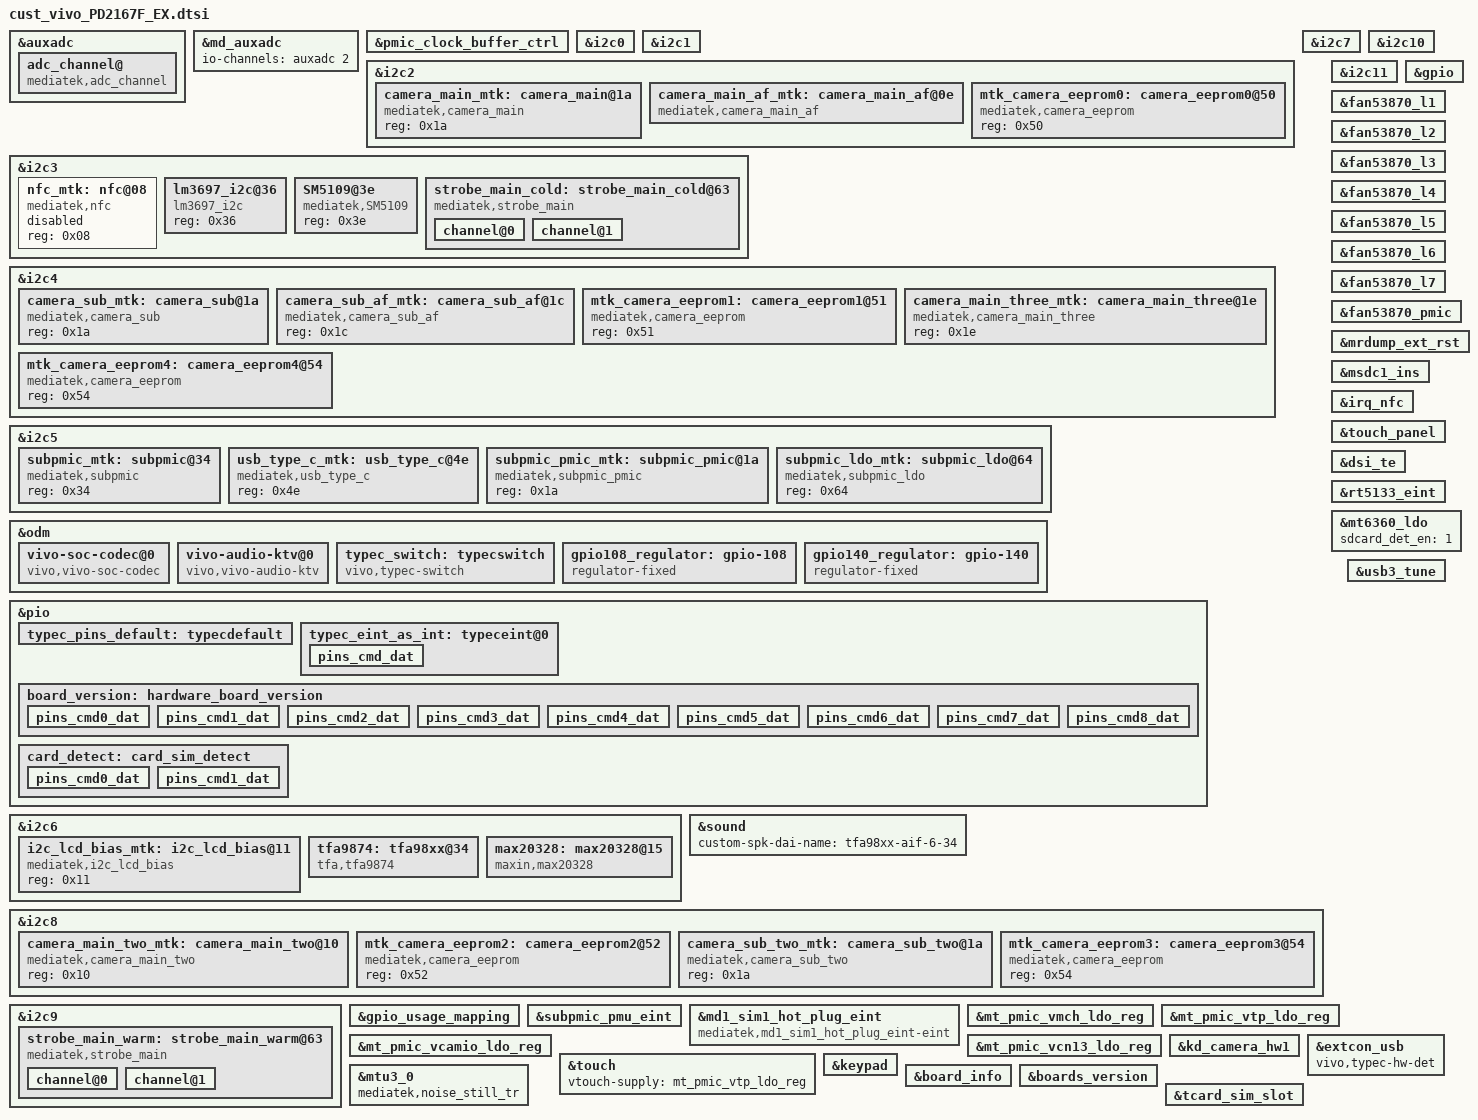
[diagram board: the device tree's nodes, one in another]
/*
 * Generated by MTK SP DrvGen Version: 3.5.160809 for MT6877.
 * 2021-08-30 17:19:41
 * Do Not Modify The File.
 * Copyright Mediatek Inc. (c) 2016.
*/

/*************************
 * ADC DTSI File
*************************/

&auxadc {
	adc_channel@ {
		compatible = "mediatek,adc_channel";
		mediatek,temperature0 = <0>;
		mediatek,temperature1 = <1>;
		mediatek,adc_fdd_rf_params_dynamic_custom_ch = <2>;
		status = "okay";
	};
};
&md_auxadc {
	io-channels = <&auxadc 2>;
};


/*************************
 * CLK_BUF DTSI File
*************************/

&pmic_clock_buffer_ctrl {
	mediatek,clkbuf-quantity = <7>;
	mediatek,clkbuf-config = <2 1 2 2 0 0 1>;
	mediatek,clkbuf-output-impedance = <3 4 3 4 0 0 3>;
	mediatek,clkbuf-controls-for-desense = <0 4 0 4 0 0 0>;
	status = "okay";
};


/*************************
 * I2C DTSI File
*************************/

&i2c0 {
	#address-cells = <1>;
	#size-cells = <0>;
	clock-frequency = <400000>;
	mediatek,use-open-drain;
	#include "fan53870.dtsi"
};

&i2c1 {
	#address-cells = <1>;
	#size-cells = <0>;
	clock-frequency = <400000>;
	mediatek,use-open-drain;
};

&i2c2 {
	#address-cells = <1>;
	#size-cells = <0>;
	clock-frequency = <400000>;
	mediatek,use-open-drain;
	camera_main_mtk:camera_main@1a {
		compatible = "mediatek,camera_main";
		reg = <0x1a>;
		status = "okay";
	};

	camera_main_af_mtk:camera_main_af@0e {
		compatible = "mediatek,camera_main_af";
		reg = <0x0e>;
		status = "okay";
	};
	mtk_camera_eeprom0:camera_eeprom0@50 {
		compatible = "mediatek,camera_eeprom";
		reg = <0x50>;
		status = "okay";
	};

};

&i2c3 {
	#address-cells = <1>;
	#size-cells = <0>;
	clock-frequency = <400000>;
	mediatek,use-open-drain;
	nfc_mtk:nfc@08 {
		compatible = "mediatek,nfc";
		reg = <0x08>;
		status = "disabled";
	};

	lm3697_i2c@36 {
		compatible = "lm3697_i2c";
		reg = <0x36>;
		status = "okay";
	};
	SM5109@3e {
		compatible = "mediatek,SM5109";
		reg = <0x3e>;
		status = "okay";
	};
	strobe_main_cold: strobe_main_cold@63 {
		compatible = "mediatek,strobe_main";
		reg = <0x63>;
		status = "okay";
		flash_enable-supply = <&gpio108_regulator>;
		torch_enable-supply = <&gpio140_regulator>;
	};
};

&i2c4 {
	#address-cells = <1>;
	#size-cells = <0>;
	clock-frequency = <400000>;
	mediatek,use-open-drain;
	camera_sub_mtk:camera_sub@1a {
		compatible = "mediatek,camera_sub";
		reg = <0x1a>;
		status = "okay";
	};
	camera_sub_af_mtk:camera_sub_af@1c {
		compatible = "mediatek,camera_sub_af";
		reg = <0x1c>;
		status = "okay";
	};
	mtk_camera_eeprom1:camera_eeprom1@51 {
		compatible = "mediatek,camera_eeprom";
		reg = <0x51>;
		status = "okay";
	};
	camera_main_three_mtk:camera_main_three@1e {
		compatible = "mediatek,camera_main_three";
		reg = <0x1e>;
		status = "okay";
	};
	mtk_camera_eeprom4:camera_eeprom4@54 {
		compatible = "mediatek,camera_eeprom";
		reg = <0x54>;
		status = "okay";
	};

};

&i2c5 {
	#address-cells = <1>;
	#size-cells = <0>;
	clock-frequency = <3400000>;
	mediatek,use-push-pull;
	subpmic_mtk:subpmic@34 {
		compatible = "mediatek,subpmic";
		reg = <0x34>;
		status = "okay";
	};

	usb_type_c_mtk:usb_type_c@4e {
		compatible = "mediatek,usb_type_c";
		reg = <0x4e>;
		status = "okay";
	};

	subpmic_pmic_mtk:subpmic_pmic@1a {
		compatible = "mediatek,subpmic_pmic";
		reg = <0x1a>;
		status = "okay";
	};

	subpmic_ldo_mtk:subpmic_ldo@64 {
		compatible = "mediatek,subpmic_ldo";
		reg = <0x64>;
		status = "okay";
	};

};

/* vivo audio dxl add start */
&odm {
	vivo-soc-codec@0 {
		compatible = "vivo,vivo-soc-codec";
		status = "okay";
	};
	vivo-audio-ktv@0 {
		compatible = "vivo,vivo-audio-ktv";
		status = "okay";
	};

	typec_switch:typecswitch {
			compatible = "vivo,typec-switch";
			interrupt-parent = <&pio>;
			interrupts = <17 IRQ_TYPE_LEVEL_LOW 17 0>;
			deb-gpios = <&pio 17 0>;
			debounce = <256000>;
			need_config_Max14743 = <1>;
			pinctrl-names = "default", "typec_eint_as_int";
			pinctrl-0 = <&typec_pins_default>;
			pinctrl-1 = <&typec_eint_as_int>;
			status = "okay";
	};
};

&pio {
	typec_pins_default: typecdefault {
	};
	typec_eint_as_int: typeceint@0 {
			pins_cmd_dat {
					pinmux = <PINMUX_GPIO17__FUNC_GPIO17>;
					slew-rate = <0>;
					/*audio_v: archer modfiy bacause cancel hardware comparator,so not the interrupt.*/
					/*bias-disable;*/
					bias-pull-up;
					input-enable;
			};
	};
};
/* vivo audio dxl add end */

&i2c6 {
	#address-cells = <1>;
	#size-cells = <0>;
	clock-frequency = <400000>;
	mediatek,use-open-drain;
	i2c_lcd_bias_mtk:i2c_lcd_bias@11 {
		compatible = "mediatek,i2c_lcd_bias";
		reg = <0x11>;
		status = "okay";
	};
	/* vivo audio dxl add start */
	tfa9874: tfa98xx@34 {
		status = "okay";
		compatible = "tfa,tfa9874";
		#sound-dai-cells = <1>;
		reg = <0x34>;
		vivo_dtbo_version = "version:5"; /*audio_v: archer add for test dtbo is update*/
		vivo,tfa98xx-version = "tfa9874";
		vivo,tfa98xx-config = "tfa98xx_PD2167F_EX.cnt";
		vivo,tfa98xx-impedance-min = <6000>;
		vivo,tfa98xx-impedance-max = <10000>;
		vivo,tfa98xx-frequency-min = <600>;
		vivo,tfa98xx-frequency-max = <900>;
		vivo,tfa98xx-Qt-min = <110>;
		reset-gpio = <&pio 111 0>;
	};

	max20328:max20328@15 {
		status = "okay";
		#sound-dai-cells = <0>;
		compatible = "maxin,max20328";
		reg = <0x15>;
		max,usbc-ic-mode = <0>; /* max20328: 0; fsa4480: 1 */
		jack-type = <1>;   /*0:3.5mm, 1:Type-c*/
		switch-type = <0>; /*0:max20328, 1:FS4480*/
	};
	/* vivo audio dxl add end */
};

/* vivo audio dxl add start */
&sound {
	custom-spk-dai-name = "tfa98xx-aif-6-34";
};
/* vivo audio dxl add end */

&i2c7 {
	#address-cells = <1>;
	#size-cells = <0>;
	clock-frequency = <400000>;
	mediatek,use-open-drain;
};

&i2c8 {
	#address-cells = <1>;
	#size-cells = <0>;
	clock-frequency = <400000>;
	mediatek,use-open-drain;
	camera_main_two_mtk:camera_main_two@10 {
		compatible = "mediatek,camera_main_two";
		reg = <0x10>;
		status = "okay";
	};
	mtk_camera_eeprom2:camera_eeprom2@52 {
		compatible = "mediatek,camera_eeprom";
		reg = <0x52>;
		status = "okay";
	};
	camera_sub_two_mtk:camera_sub_two@1a {
		compatible = "mediatek,camera_sub_two";
		reg = <0x1a>;
		status = "okay";
	};
	mtk_camera_eeprom3:camera_eeprom3@54 {
		compatible = "mediatek,camera_eeprom";
		reg = <0x54>;
		status = "okay";
	};

};

&i2c9 {
	#address-cells = <1>;
	#size-cells = <0>;
	clock-frequency = <400000>;
	mediatek,use-open-drain;
	strobe_main_warm: strobe_main_warm@63 {
		compatible = "mediatek,strobe_main";
		reg = <0x63>;
		status = "okay";
		flash_enable-supply = <&gpio108_regulator>;
		torch_enable-supply = <&gpio140_regulator>;
	};
};

&i2c10 {
	#address-cells = <1>;
	#size-cells = <0>;
	clock-frequency = <400000>;
	mediatek,use-open-drain;
};

&i2c11 {
	#address-cells = <1>;
	#size-cells = <0>;
	clock-frequency = <400000>;
	mediatek,use-open-drain;
};



/*************************
 * GPIO DTSI File
*************************/

&gpio_usage_mapping {
	GPIO_RF_PWREN_RST_PIN = <&pio 75 0>;
	GPIO_FDD_BAND_SUPPORT_DETECT_1ST_PIN = <&pio 92 0>;
	GPIO_FDD_BAND_SUPPORT_DETECT_2ND_PIN = <&pio 35 0>;
	GPIO_SIM2_SIO = <&pio 170 0>;
	GPIO_SIM2_SCLK = <&pio 171 0>;
	GPIO_SIM2_SRST = <&pio 172 0>;
	GPIO_SIM1_SRST = <&pio 173 0>;
	GPIO_SIM1_SCLK = <&pio 174 0>;
	GPIO_SIM1_SIO = <&pio 175 0>;
	GPIO_SIM1_HOT_PLUG = <&pio 176 0>;
};

&gpio{
	gpio_init_default = <0 0 0 0 1 1 1>,
		<1 0 0 0 1 0 1>,
		<2 0 0 0 1 1 1>,
		<3 0 0 0 0 0 1>, /* modify by dxl to disable max20328 INT pullen */
		<4 0 0 0 1 1 1>,
		<5 0 0 0 1 1 1>,
		<6 0 0 0 0 0 1>,
		<7 0 0 0 0 0 0>,
		<8 0 0 0 1 1 0>,
		<9 0 0 0 1 0 0>,
		<10 0 1 0 1 0 1>,
		<11 0 0 0 1 0 0>,
		<12 0 1 0 0 0 0>,//fan53870 rst
		<13 0 0 0 1 0 0>,//fan53870 int
		<14 0 0 0 1 1 1>,
		<15 0 1 0 0 0 1>,
		<16 7 0 0 1 1 0>,
		<17 7 0 0 1 1 0>,
		<18 0 1 0 0 0 0>,
		<19 0 1 0 0 0 0>,
		<20 0 0 0 0 0 1>,
		<21 0 1 0 1 0 0>,
		<22 0 1 0 1 0 0>,
		<23 7 0 0 1 1 0>,
		<24 0 0 0 1 1 0>,
		<25 1 0 0 0 0 0>,
		<26 1 0 0 1 1 0>,
		<27 0 1 1 1 1 0>,
		<28 1 0 0 1 1 0>,
		<29 0 0 0 0 0 1>,
		<30 0 0 0 0 0 1>,
		<31 0 0 0 0 0 1>,
		<32 1 0 0 1 1 0>,
		<33 1 0 0 1 1 0>,
		<34 1 0 0 1 1 0>,
		<35 0 0 0 1 1 0>,
		<36 1 0 0 1 1 1>,
		<37 1 0 0 1 1 1>,
		<38 1 0 0 1 1 1>,
		<39 1 0 0 1 0 1>,
		<40 0 1 0 0 0 0>,
		<41 1 0 0 0 0 1>,
		<42 1 0 0 0 0 1>,
		<43 1 0 0 1 0 1>,
		<44 1 0 0 1 0 1>,
		<45 1 0 0 1 1 1>,
		<46 1 0 0 0 0 0>,
		<47 1 0 0 0 0 0>,
		<48 1 0 0 0 0 0>,
		<49 1 0 0 0 0 0>,
		<50 1 0 0 1 0 0>,
		<51 1 0 0 1 0 0>,
		<52 1 0 0 1 0 0>,
		<53 1 0 0 1 0 0>,
		<54 1 0 0 1 0 1>,
		<55 1 0 0 1 0 0>,
		<56 1 0 0 1 0 0>,
		<57 1 0 0 1 0 0>,
		<58 1 0 0 1 0 0>,
		<59 1 0 0 1 0 0>,
		<60 1 0 0 0 0 1>,
		<61 1 0 0 0 0 1>,
		<62 1 0 0 0 0 1>,
		<63 1 0 0 0 0 1>,
		<64 1 0 0 1 1 1>,//fan53870 i2c0 scl
		<65 1 0 0 1 1 1>,//fan53870 i2c0 sda
		<66 1 0 0 1 0 1>,
		<67 1 0 0 1 0 1>,
		<68 1 0 0 0 0 0>,
		<69 1 0 0 1 0 0>,
		<70 1 0 0 1 0 1>,
		<71 1 0 0 0 0 1>,
		<72 1 0 0 0 0 1>,
		<73 1 0 0 0 0 1>,
		<74 1 0 0 0 0 1>,
		<75 0 1 1 1 0 1>,
		<76 1 0 0 0 0 1>,
		<77 0 0 0 1 1 0>,
		<78 1 0 0 0 0 1>,
		<79 1 0 0 0 0 1>,
		<80 0 0 0 1 1 0>,
		<81 0 0 0 1 1 0>,
		<82 1 0 0 0 0 0>,
		<83 1 0 0 1 0 0>,
		<84 1 0 0 0 0 0>,
		<85 1 0 0 1 0 0>,
		<86 1 0 0 1 0 1>,
		<87 0 0 0 1 1 0>,
		<88 1 0 0 0 0 1>,
		<89 0 0 0 1 1 0>,
		<90 1 0 0 0 0 1>,
		<91 1 0 0 0 0 1>,
		<92 0 0 0 1 1 0>,
		<93 1 0 0 0 0 1>,
		<94 0 0 0 1 1 0>,
		<95 1 0 0 0 0 1>,
		<96 0 0 0 1 1 0>,
		<97 1 0 0 0 0 1>,
		<98 0 1 0 1 0 1>,
		<99 0 1 0 1 0 1>,
		<100 0 1 0 1 0 1>,
		<101 0 1 0 1 0 1>,
		<102 1 0 0 1 1 0>,
		<103 1 0 0 1 1 0>,
		<104 1 0 0 1 1 0>,
		<105 1 0 0 1 1 0>,
		<106 1 0 0 1 1 0>,
		<107 0 1 1 0 0 1>,
		<108 0 1 0 0 0 0>,//flash en
		<109 0 1 0 1 0 0>,//usb sel
		<110 0 1 0 1 0 0>,//bat id ctl
		<111 0 1 0 1 0 0>,
		<112 1 0 0 1 1 0>,
		<113 0 0 0 1 1 0>,
		<114 0 0 0 1 1 0>,
		<115 2 0 0 1 0 1>,
		<116 1 0 0 1 1 1>,
		<117 0 0 0 1 1 0>,
		<118 0 0 0 1 1 0>,
		<119 0 0 0 1 1 0>,
		<120 1 0 0 1 1 0>,
		<121 0 0 0 1 1 0>,
		<122 7 0 0 1 1 1>,
		<123 7 0 0 1 1 0>,
		<124 7 0 0 1 1 0>,
		<125 7 0 0 1 1 0>,
		<126 2 0 0 1 0 0>,
		<127 2 0 0 1 0 0>,
		<128 2 0 0 1 1 1>,
		<129 2 0 0 1 0 1>,
		<130 2 0 0 1 1 1>,
		<131 2 0 0 1 1 1>,
		<132 1 0 0 1 1 1>,
		<133 1 0 0 1 1 1>,
		<134 1 0 0 1 1 1>,
		<135 1 0 0 1 1 1>,
		<136 1 0 0 0 0 1>,//cam2_3 i2c8 scl
		<137 1 0 0 0 0 1>,//cam2_3 i2c8 sda
		<138 0 1 0 1 0 1>,
		<139 0 1 0 1 0 0>,
		<140 0 1 0 0 0 0>,//flash torch
		<141 0 1 0 1 0 1>,
		<142 0 1 0 1 0 0>,
		<143 1 0 0 0 0 1>,//cam0 i2c2 scl
		<144 1 0 0 0 0 1>,//cam0 i2c2 sda
		<145 1 0 0 0 0 1>,//cam1_4 i2c4 scl
		<146 1 0 0 0 0 1>,//cam1_4 i2c4 sda
		<147 1 0 0 1 1 1>,//flash i2c9 scl front
		<148 1 0 0 1 1 1>,//flash i2c9 sda front
		<149 0 1 0 0 0 0>,//cam0 clk0
		<150 0 1 0 0 0 0>,//cam1 clk1
		<151 0 1 0 0 0 0>,//cam4 clk2
		<152 0 1 0 0 0 0>,//cam2 clk3
		<153 0 1 0 0 0 0>,//cam3 clk4
		<154 0 0 0 1 1 0>,
		<155 0 1 0 0 0 0>,//cam0 rst0
		<156 0 0 0 1 1 0>,
		<157 0 1 0 0 0 0>,//cam1 rst1
		<158 0 0 0 1 1 0>,
		<159 0 1 0 0 0 0>,//cam4 rst2
		<160 0 0 0 1 1 0>,
		<161 0 1 0 0 0 0>,//cam3 rst3
		<162 0 1 0 0 0 0>,//cam2_3 dvdd
		<163 0 1 0 0 0 0>,//cam2 rst4
		<164 1 0 0 1 1 0>,
		<165 1 0 0 0 0 0>,
		<166 1 0 0 1 1 0>,
		<167 1 0 0 1 1 0>,
		<168 1 0 0 1 1 0>,
		<169 1 0 0 1 1 0>,
		<170 1 0 0 1 1 1>,
		<171 1 0 0 0 0 1>,
		<172 1 0 0 0 0 1>,
		<173 1 0 0 0 0 1>,
		<174 1 0 0 0 0 1>,
		<175 1 0 0 1 1 1>,
		<176 1 0 0 0 0 1>,
		<177 0 0 0 0 0 1>,
		<178 1 0 0 1 0 0>,
		<179 1 0 0 1 0 0>,
		<180 1 0 0 1 1 1>,
		<181 1 0 0 1 1 1>,
		<182 1 0 0 0 1 0>,
		<183 1 0 0 0 1 0>,
		<184 1 0 0 0 0 0>,
		<185 1 0 0 0 0 0>,
		<186 1 0 0 1 1 1>,//nfc flash i2c3 scl front
		<187 1 0 0 1 1 1>,//nfc flash i2c3 sda front
		<188 0 1 0 1 1 0>,
		<189 0 1 0 1 1 0>,
		<190 1 0 0 1 1 0>,
		<191 1 0 0 1 1 0>,
		<192 1 0 0 1 1 0>,
		<193 0 0 0 1 1 0>,
		<194 0 0 0 1 1 0>,
		<195 0 0 0 1 1 0>,
		<196 0 0 0 1 0 0>,
		<197 0 0 0 1 0 0>,
		<198 0 0 0 1 0 0>,
		<199 0 0 0 1 0 0>,
		<200 0 0 0 1 0 0>,
		<201 0 0 0 1 0 0>,
		<202 0 0 0 1 0 0>,
		<203 0 0 0 1 0 0>,
		<204 0 0 0 1 0 0>,
		<205 0 0 0 1 0 0>,
		<206 0 0 0 1 0 0>,
		<207 0 0 0 1 0 0>,
		<208 0 0 0 1 0 0>;
};

/* hope add fan53870 pmic start*/
&fan53870_l1 {
	regulator-name = "fan53870_l1";
	regulator-default-on = <1>; /* 0:skip, 1: off, 2:on */
	status = "okay";
};

&fan53870_l2 {
	regulator-name = "fan53870_l2";
	regulator-default-on = <1>; /* 0:skip, 1: off, 2:on */
	status = "okay";
};

&fan53870_l3 {
	regulator-name = "fan53870_l3";
	regulator-default-on = <1>; /* 0:skip, 1: off, 2:on */
	status = "okay";
};

&fan53870_l4 {
	regulator-name = "fan53870_l4";
	regulator-default-on = <1>; /* 0:skip, 1: off, 2:on */
	status = "okay";
};

&fan53870_l5 {
	regulator-name = "fan53870_l5";
	regulator-default-on = <1>; /* 0:skip, 1: off, 2:on */
	status = "okay";
};

&fan53870_l6 {
	regulator-name = "fan53870_l6";
	regulator-default-on = <1>; /* 0:skip, 1: off, 2:on */
	status = "okay";
};

&fan53870_l7 {
	regulator-name = "fan53870_l7";
	regulator-default-on = <1>; /* 0:skip, 1: off, 2:on */
	status = "okay";
};
/* hope add fan53870 pmic end*/

/*hope add fan53870 for pmic irq  start */
&fan53870_pmic {
	fan53870,irq = <&pio 13 0>;
	fan53870,reset = <&pio 12 0>;
	interrupt-parent = <&pio>;
	interrupts = <13 IRQ_TYPE_EDGE_RISING 13 0>;
	deb-gpios = <&pio 13 0>;
	fan53870,init-settings = <0x13 0x03>,<0x14 0x00>;
	debounce = <256000>;
	status = "okay";
};
/*hope add fan53870 for pmic irq end */

/*************************
 * EINT DTSI File
*************************/

#include <dt-bindings/interrupt-controller/irq.h>
#include <dt-bindings/interrupt-controller/arm-gic.h>

&mrdump_ext_rst {
	interrupt-parent = <&pio>;
	interrupts = <0 IRQ_TYPE_LEVEL_LOW>;
	status = "okay";
};

&msdc1_ins {
	interrupt-parent = <&pio>;
	interrupts = <3 IRQ_TYPE_LEVEL_LOW>;
	status = "okay";
};

&subpmic_pmu_eint {
	interrupt-parent = <&pio>;
	interrupts = <4 IRQ_TYPE_EDGE_FALLING>;
	status = "okay";
};

&irq_nfc {
	interrupt-parent = <&pio>;
	interrupts = <8 IRQ_TYPE_LEVEL_HIGH>;
	status = "okay";
};

&touch_panel {
	interrupt-parent = <&pio>;
	interrupts = <14 IRQ_TYPE_LEVEL_LOW>;
	status = "okay";
};

&dsi_te {
	interrupt-parent = <&pio>;
	interrupts = <37 IRQ_TYPE_EDGE_RISING>;
	status = "okay";
};

&rt5133_eint {
	interrupt-parent = <&pio>;
	interrupts = <162 IRQ_TYPE_LEVEL_LOW>;
	status = "okay";
};



/*************************
 * MD1_EINT DTSI File
*************************/

&md1_sim1_hot_plug_eint {
	compatible = "mediatek,md1_sim1_hot_plug_eint-eint";
	interrupts = <0 8>;
	debounce = <0 100000>;
	dedicated = <0 0>;
	src_pin = <0 1>;
	sockettype = <0 0>;
	status = "okay";
};




/*************************
 * PMIC DTSI File
*************************/
&mt6360_ldo {
	sdcard_det_en = <1>;
};

&mt_pmic_vmch_ldo_reg {
	regulator-name = "vmch";
	regulator-default-on = <1>; /* 0:skip, 1: off, 2:on */
	status = "okay";
};

&mt_pmic_vtp_ldo_reg {
	regulator-name = "vmch";
	regulator-default-on = <1>; /* 0:skip, 1: off, 2:on */
	status = "okay";
};
&mt_pmic_vcamio_ldo_reg {
	regulator-name = "vcamio";
	regulator-default-on = <1>; /* 0:skip, 1: off, 2:on */
	status = "okay";
};
&mt_pmic_vtp_ldo_reg {
	regulator-name = "vtp";
	regulator-default-on = <1>; /* 0:skip, 1: off, 2:on */
	status = "okay";
};
&mt_pmic_vcn13_ldo_reg{
	regulator-name = "vcn13";
	regulator-default-on = <1>; /* 0:skip, 1: off, 2:on */
	status = "okay";
};

&kd_camera_hw1 {
	cam0_vcamio-supply = <&fan53870_l7>;/*dovdd ldo7*/
	cam1_vcamio-supply = <&fan53870_l7>;
	cam2_vcamio-supply = <&fan53870_l7>;
	cam3_vcamio-supply = <&fan53870_l7>;
	cam4_vcamio-supply = <&fan53870_l7>;

	cam0_vcama-supply = <&fan53870_l4>;/*avdd*/
	cam1_vcama-supply = <&fan53870_l3>;
	cam2_vcama-supply = <&fan53870_l5>;
	cam3_vcama-supply = <&fan53870_l5>;
	cam4_vcama-supply = <&fan53870_l3>;

	cam0_vcamd-supply = <&fan53870_l2>;/*dvdd*/
	cam1_vcamd-supply = <&fan53870_l1>;

	//cam0_vcamaf-supply = <&fan53870_l6>;/*afvdd*/
	//cam1_vcamaf-supply = <&fan53870_l6>;

	cam0_enable_sensor = "s5kgw1sd03pd2167f_mipi_raw";
	cam1_enable_sensor = "s5kjnvsq04pd2167f_mipi_raw s5kjn1sq03pd2167f_mipi_raw";
	cam2_enable_sensor = "ov8856pd2167f_mipi_raw";
	cam3_enable_sensor = "hi846pd2167f_mipi_raw";
	cam4_enable_sensor = "ov02b10pd2167f_mipi_raw";
	status = "okay";
};

&odm {
	gpio108_regulator:gpio-108 {
			compatible = "regulator-fixed";
			regulator-name = "gpio108_regulator";
			gpio = <&pio 108 0x0>;
			enable-active-high;
			status = "okay";
	};

	gpio140_regulator:gpio-140 {
			compatible = "regulator-fixed";
			regulator-name = "gpio140_regulator";
			gpio = <&pio 140 0x0>;
			enable-active-high;
			status = "okay";
	};
};
/*hope add main af pmic power start*/
&camera_main_af_mtk {
	vcamaf-supply = <&fan53870_l6>;
	//vcamaf_b-supply = <&L6P>;
};
/*hope add main af pmic power end*/

/*hope add for flashlight channel start*/
/*&strobe_main {
	decouple = <0>;
	channel@0 {
		type = <1>;
		ct = <0>;
		part = <0>;
	};
	channel@1 {
		type = <1>;
		ct = <1>;
		part = <0>;
	};
};*/

&strobe_main_warm {
	decouple = <0>;
	channel@0 {
		type = <1>;
		ct = <0>;
		part = <1>;
	};
	channel@1 {
		type = <1>;
		ct = <1>;
		part = <1>;
	};
};
&strobe_main_cold {
	decouple = <0>;
	channel@0 {
		type = <1>;
		ct = <0>;
		part = <0>;
	};
	channel@1 {
		type = <1>;
		ct = <1>;
		part = <0>;
	};
};
/*hope add for flashlight channel end*/

/*&mt_pmic_vcn33_2_wifi_ldo_reg {
	regulator-name = "vcn33_2_mcu";
	regulator-default-on = <0>;
	status = "okay";
};*/
&touch {
	vtouch-supply = <&mt_pmic_vtp_ldo_reg>;
	status = "okay";
};



/* yangtao add for usb start */
&usb3_tune {
	u2_vrt_ref = <0x7>;
	u2_term_ref = <0x5>;
	u2_enhance = <0x3>;
	u2_vrt_ref_host = <0x5>;
	u2_term_ref_host = <0x5>;
	u2_enhance_host = <0x2>;
};

&extcon_usb {
	vivo,typec-hw-det;
};
&mtu3_0 {
	mediatek,noise_still_tr;
};
/* yangtao add for usb end */



/*************************
 * KPD DTSI File
*************************/

&keypad {
	mediatek,kpd-key-debounce = <1024>;
	mediatek,kpd-sw-pwrkey = <116>;
	mediatek,kpd-hw-pwrkey = <8>;
	mediatek,kpd-sw-rstkey  = <114>;
	mediatek,kpd-hw-rstkey = <17>;
	mediatek,kpd-use-extend-type = <0>;
	/*HW Keycode [0~71] -> Linux Keycode*/
	mediatek,kpd-hw-map-num = <72>;
	mediatek,kpd-hw-init-map = <115 0 0 0 0 0 0 0 0 0 0 0 0 0 0 0 0 0 0 0 0 0 0 0 0 0 0 0 0 0 0 0 0 0 0 0 0 0 0 0 0 0 0 0 0 0 0 0 0 0 0 0 0 0 0 0 0 0 0 0 0 0 0 0 0 0 0 0 0 0 0 0 >;
	mediatek,kpd-pwrkey-eint-gpio = <0>;
	mediatek,kpd-pwkey-gpio-din  = <0>;
	mediatek,kpd-hw-dl-key0 = <17>;
	mediatek,kpd-hw-dl-key1 = <0>;
	mediatek,kpd-hw-dl-key2 = <8>;
	mediatek,kpd-hw-recovery-key = <17>;
	mediatek,kpd-hw-factory-key = <0>;
	status = "okay";
};

/* add board info fdt node by corebsp begin */
&board_info {
	vivo,vendor_project_name = "PD2167F_EX";
	vivo,vendor_project_cpu = "MT6877T";
	vivo,vendor_project_freq = "2.5";
	vivo,vendor_project_cpunum = <8>;
	vivo,vendor_cpu_set = "Dimensity_920";
};

&boards_version {
	pinctrl-names = "default";
	pinctrl-0 = <&board_version>;
	gpio_nums = <9>;
	gpios = <92 91 90 89 88 87 81 24 35>;
	/* if use pcb version,need to define:pcb_gpio_nums pcb_gpios pcb_maps_nums pcb_gpios_maps */
	/*pcb_gpio_nums = <2>;*/
	/*pcb_gpios = <107 108>;*/
	/* 00:MP_0.1, 01:MP_0.2, 10:MP_0.3, 11:MP_0.4 */
	/*pcb_maps_nums = <8>;*/
	/*pcb_gpios_maps = <0x0 0x1 0x1 0x2 0x2 0x3 0x3 0x4>;*/
};

&tcard_sim_slot {
	pinctrl-names = "default";
	pinctrl-0 = <&card_detect>;
	vivo,sim1-need-detect;
	vivo,sim2-need-detect;
	vivo,sim1-detect-high;
	vivo,sim2-detect-high;

	card-detect-sim1,gpios = <&pio 176 0x0>;
	card-detect-sim2,gpios = <&pio 176 0x0>;
};

&pio {
	board_version: hardware_board_version {
		pins_cmd0_dat {
			pinmux = <PINMUX_GPIO81__FUNC_GPIO81>;
			slew-rate = <0>;
		};
		pins_cmd1_dat {
			pinmux = <PINMUX_GPIO87__FUNC_GPIO87>;
			slew-rate = <0>;
		};
		pins_cmd2_dat {
			pinmux = <PINMUX_GPIO88__FUNC_GPIO88>;
			slew-rate = <0>;
		};
		pins_cmd3_dat {
			pinmux = <PINMUX_GPIO89__FUNC_GPIO89>;
			slew-rate = <0>;
		};
		pins_cmd4_dat {
			pinmux = <PINMUX_GPIO90__FUNC_GPIO90>;
			slew-rate = <0>;
		};
		pins_cmd5_dat {
			pinmux = <PINMUX_GPIO91__FUNC_GPIO91>;
			slew-rate = <0>;
		};
		pins_cmd6_dat {
			pinmux = <PINMUX_GPIO92__FUNC_GPIO92>;
			slew-rate = <0>;
		};
		pins_cmd7_dat {
			pinmux = <PINMUX_GPIO24__FUNC_GPIO24>;
			slew-rate = <0>;
		};
		pins_cmd8_dat {
			pinmux = <PINMUX_GPIO35__FUNC_GPIO35>;
			slew-rate = <0>;
		};
	};

	card_detect: card_sim_detect {
		pins_cmd0_dat {
			pinmux = <PINMUX_GPIO176__FUNC_MD_INT1_C2K_UIM0_HOT_PLUG>;
			slew-rate = <0>;
			bias-disable;
		};
		pins_cmd1_dat {
			pinmux = <PINMUX_GPIO177__FUNC_MD_INT2_C2K_UIM1_HOT_PLUG>;
			slew-rate = <0>;
			bias-disable;
		};
	};
};
/* add board info fdt node by corebsp end */
